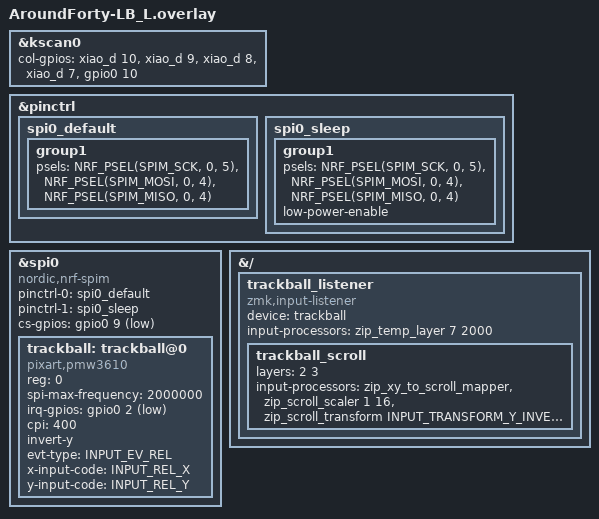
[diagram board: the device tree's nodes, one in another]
#include "AroundForty-LB.dtsi"

#include <zephyr/dt-bindings/input/input-event-codes.h>
#include <dt-bindings/zmk/input_transform.h>
#include <input/processors.dtsi>

&kscan0 {
        col-gpios
            = <&xiao_d 10 GPIO_ACTIVE_HIGH>
            , <&xiao_d 9 GPIO_ACTIVE_HIGH> 
            , <&xiao_d 8 GPIO_ACTIVE_HIGH> 
            , <&xiao_d 7 GPIO_ACTIVE_HIGH> 
            , <&gpio0 10 GPIO_ACTIVE_HIGH>
            ;
};

&pinctrl {
    spi0_default: spi0_default {
        group1 {
            psels = <NRF_PSEL(SPIM_SCK, 0, 5)>,
                <NRF_PSEL(SPIM_MOSI, 0, 4)>,
                <NRF_PSEL(SPIM_MISO, 0, 4)>;
        };
    };

    spi0_sleep: spi0_sleep {
        group1 {
            psels = <NRF_PSEL(SPIM_SCK, 0, 5)>,
                <NRF_PSEL(SPIM_MOSI, 0, 4)>,
                <NRF_PSEL(SPIM_MISO, 0, 4)>;
            low-power-enable;
        };
    };
};

&spi0 {
    status = "okay";
    compatible = "nordic,nrf-spim";
    pinctrl-0 = <&spi0_default>;
    pinctrl-1 = <&spi0_sleep>;
    pinctrl-names = "default", "sleep";
    cs-gpios = <&gpio0 9 GPIO_ACTIVE_LOW>;

    trackball: trackball@0 {
        status = "okay";
        compatible = "pixart,pmw3610";
        reg = <0>;
        spi-max-frequency = <2000000>;
        irq-gpios = <&gpio0 2 (GPIO_ACTIVE_LOW | GPIO_PULL_UP)>;

        /* 旧 CONFIG_PMW3610_CPI=400 / CONFIG_PMW3610_CPI_DIVIDOR=1 相当 */
        cpi = <400>;

        /* 旧 CONFIG_PMW3610_ORIENTATION_180=y 相当（Y 軸のみ反転） */
        invert-y;

        evt-type = <INPUT_EV_REL>;
        x-input-code = <INPUT_REL_X>;
        y-input-code = <INPUT_REL_Y>;
    };
};

/* トラックボールのイベントを受けるリスナー
 *
 * 旧ドライバが持っていた automouse-layer / scroll-layers は
 * ZMK 本体の input-processor 側へ移動したため、ここで再現する。
 */
&{/} {
    trackball_listener: trackball_listener {
        compatible = "zmk,input-listener";
        device = <&trackball>;

        /* 旧 automouse-layer = <7>, CONFIG_PMW3610_AUTOMOUSE_TIMEOUT_MS=2000 相当 */
        input-processors = <&zip_temp_layer 7 2000>;

        /* 旧 scroll-layers = <2 3> 相当
         * ・XY をホイールへ割り当て
         * ・CONFIG_PMW3610_SCROLL_TICK=16 相当のスケーリング（16 カウントで 1 ノッチ）
         * ・縦方向の符号を旧ドライバに合わせて反転（横は CONFIG_PMW3610_INVERT_SCROLL_X=y 相当で反転なし）
         */
        trackball_scroll {
            layers = <2 3>;
            input-processors =
                <&zip_xy_to_scroll_mapper>,
                <&zip_scroll_scaler 1 16>,
                <&zip_scroll_transform INPUT_TRANSFORM_Y_INVERT>;
        };
    };
};
